# R7FA6M4AF register map
Vendor: Renesas Electronics Corporation; Series: RA6; File version: 1.30.00
CPU: CM33 r0p4, little endian, MPU, FPU, VTOR, 4 interrupt priority bits, 96 interrupts
Registers are 8-bit, read-write, reset 0x0 unless marked. A register's access mark holds for its fields unless they carry their own. Offsets are from the block's base; [hi:lo] are bit positions.

## DMAC0 — Direct memory access controller 0
Base 0x40005000
Same registers: DMAC1 0x40005040, DMAC2 0x40005080, DMAC3 0x400050C0, DMAC4 0x40005100, DMAC5 0x40005140, DMAC6 0x40005180, DMAC7 0x400051C0
0x00 DMSAR 32-bit — DMA Source Address Register
0x04 DMDAR 32-bit — DMA Destination Address Register
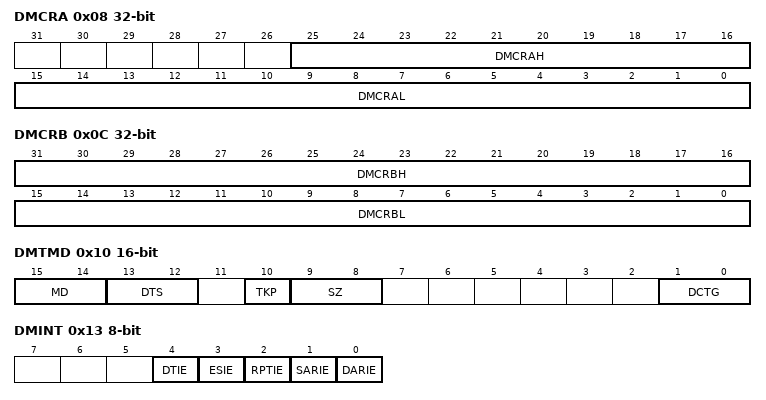
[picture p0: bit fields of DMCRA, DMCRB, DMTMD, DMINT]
0x08 DMCRA 32-bit — DMA Transfer Count Register
  [25:16] DMCRAH — Upper bits of transfer count
  [15:0] DMCRAL — Lower bits of transfer count
0x0C DMCRB 32-bit — DMA Block Transfer Count Register
  [31:16] DMCRBH — Specifies the number of block, repeat or repeat,block transfer operations.
  [15:0] DMCRBL — Functions as a number of block, repeat or repeat,block transfer counter.
0x10 DMTMD 16-bit — DMA Transfer Mode Register
  [15:14] MD — Transfer Mode Select
  [13:12] DTS — Repeat Area Select
  [10] TKP — Transfer Keeping
  [9:8] SZ — Transfer Data Size Select
  [1:0] DCTG — Transfer Request Source Select
0x13 DMINT — DMA Interrupt Setting Register
  [4] DTIE — Transfer End Interrupt Enable
  [3] ESIE — Transfer Escape End Interrupt Enable
  [2] RPTIE — Repeat Size End Interrupt Enable
  [1] SARIE — Source Address Extended Repeat Area Overflow Interrupt Enable
  [0] DARIE — Destination Address Extended Repeat Area Overflow Interrupt Enable
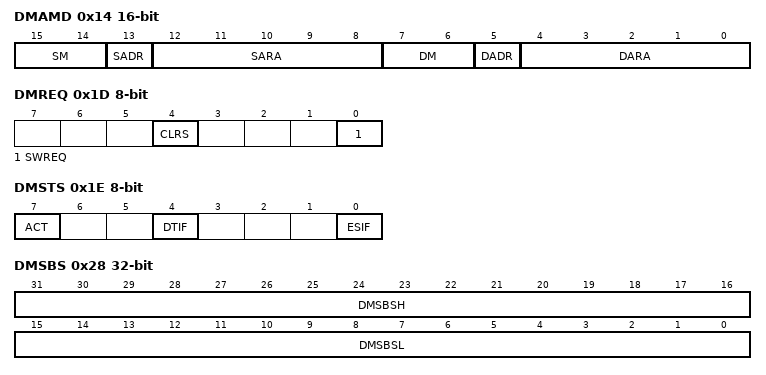
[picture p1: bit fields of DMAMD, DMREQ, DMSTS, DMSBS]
0x14 DMAMD 16-bit — DMA Address Mode Register
  [15:14] SM — Source Address Update Mode
  [13] SADR — Source Address Update Select After Reload
  [12:8] SARA — Source Address Extended Repeat Area
  [7:6] DM — Destination Address Update Mode
  [5] DADR — Destination Address Update Select After Reload
  [4:0] DARA — Destination Address Extended Repeat Area
0x18 DMOFR 32-bit — DMA Offset Register
0x1C DMCNT — DMA Transfer Enable Register
  [0] DTE — DMA Transfer Enable
0x1D DMREQ — DMA Software Start Register
  [4] CLRS — DMA Software Start Bit Auto Clear Select
  [0] SWREQ — DMA Software Start
0x1E DMSTS — DMA Status Register
  [7] ACT ro — DMAC Active Flag
  [4] DTIF — Transfer End Interrupt Flag
  [0] ESIF — Transfer Escape End Interrupt Flag
0x20 DMSRR 32-bit — DMA Source Reload Address Register
0x24 DMDRR 32-bit — DMA Destination Reload Address Register
0x28 DMSBS 32-bit — DMA Source Buffer Size Register
  [31:16] DMSBSH — Specifies the repeat,area size in repeat,block transfer mode
  [15:0] DMSBSL — Functions as data transfer counter in repeat,block transfer mode
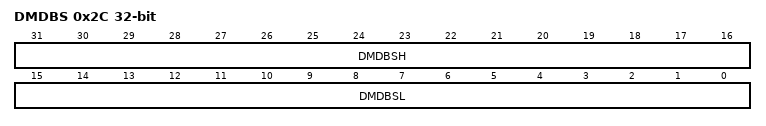
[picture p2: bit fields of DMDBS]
0x2C DMDBS 32-bit — DMA Destination Buffer Size Register
  [31:16] DMDBSH — Specifies the repeat,area size in repeat,block transfer mode.
  [15:0] DMDBSL — Functions as data transfer counter in repeat,block transfer mode.
0x30 DMBWR — DMA Bufferable Write Enable Register
  [0] BWE — Bufferable Write Enable

## DMA — DMAC Module Activation
Base 0x40005200
0x00 DMAST — DMA Module Activation Register
  [0] DMST — DMAC Operation Enable
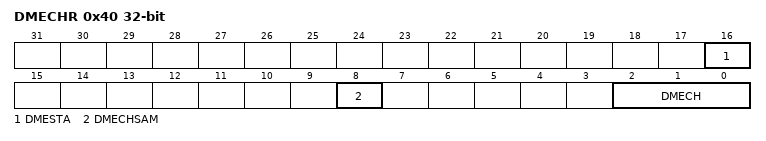
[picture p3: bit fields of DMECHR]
0x40 DMECHR 32-bit — DMAC Error Channel Register
  [16] DMESTA — DMAC Error Status
  [8] DMECHSAM ro — DMAC Error channel Security Attribution Monitor
  [2:0] DMECH ro — DMAC Error channel

## DTC — Data Transfer Controller
Base 0x40005400
0x00 DTCCR reset 0x8 — DTC Control Register
  [4] RRS — DTC Transfer Information Read Skip Enable
0x04 DTCVBR 32-bit — DTC Vector Base Register
0x0C DTCST — DTC Module Start Register
  [0] DTCST — DTC Module Start
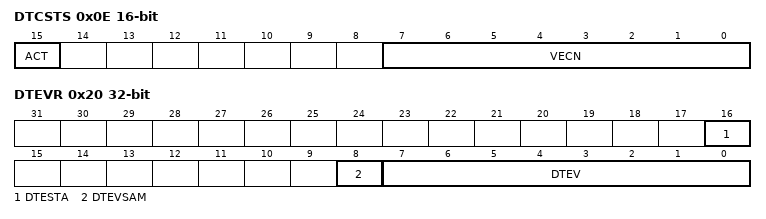
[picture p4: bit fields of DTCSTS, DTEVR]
0x0E DTCSTS 16-bit ro — DTC Status Register
  [15] ACT — DTC Active Flag
  [7:0] VECN — DTC,Activating Vector Number Monitoring
0x10 DTCCR_SEC reset 0x8 — DTC Control Register for secure Region
  [4] RRS — DTC Transfer Information Read Skip Enable for Secure
0x14 DTCVBR_SEC 32-bit — DTC Vector Base Register for secure Region
0x20 DTEVR 32-bit — DTC Error Vector Register
  [16] DTESTA — DTC Error Status Flag
  [8] DTEVSAM ro — DTC Error Vector Number SA Monitor
  [7:0] DTEV ro — DTC Error Vector Number
